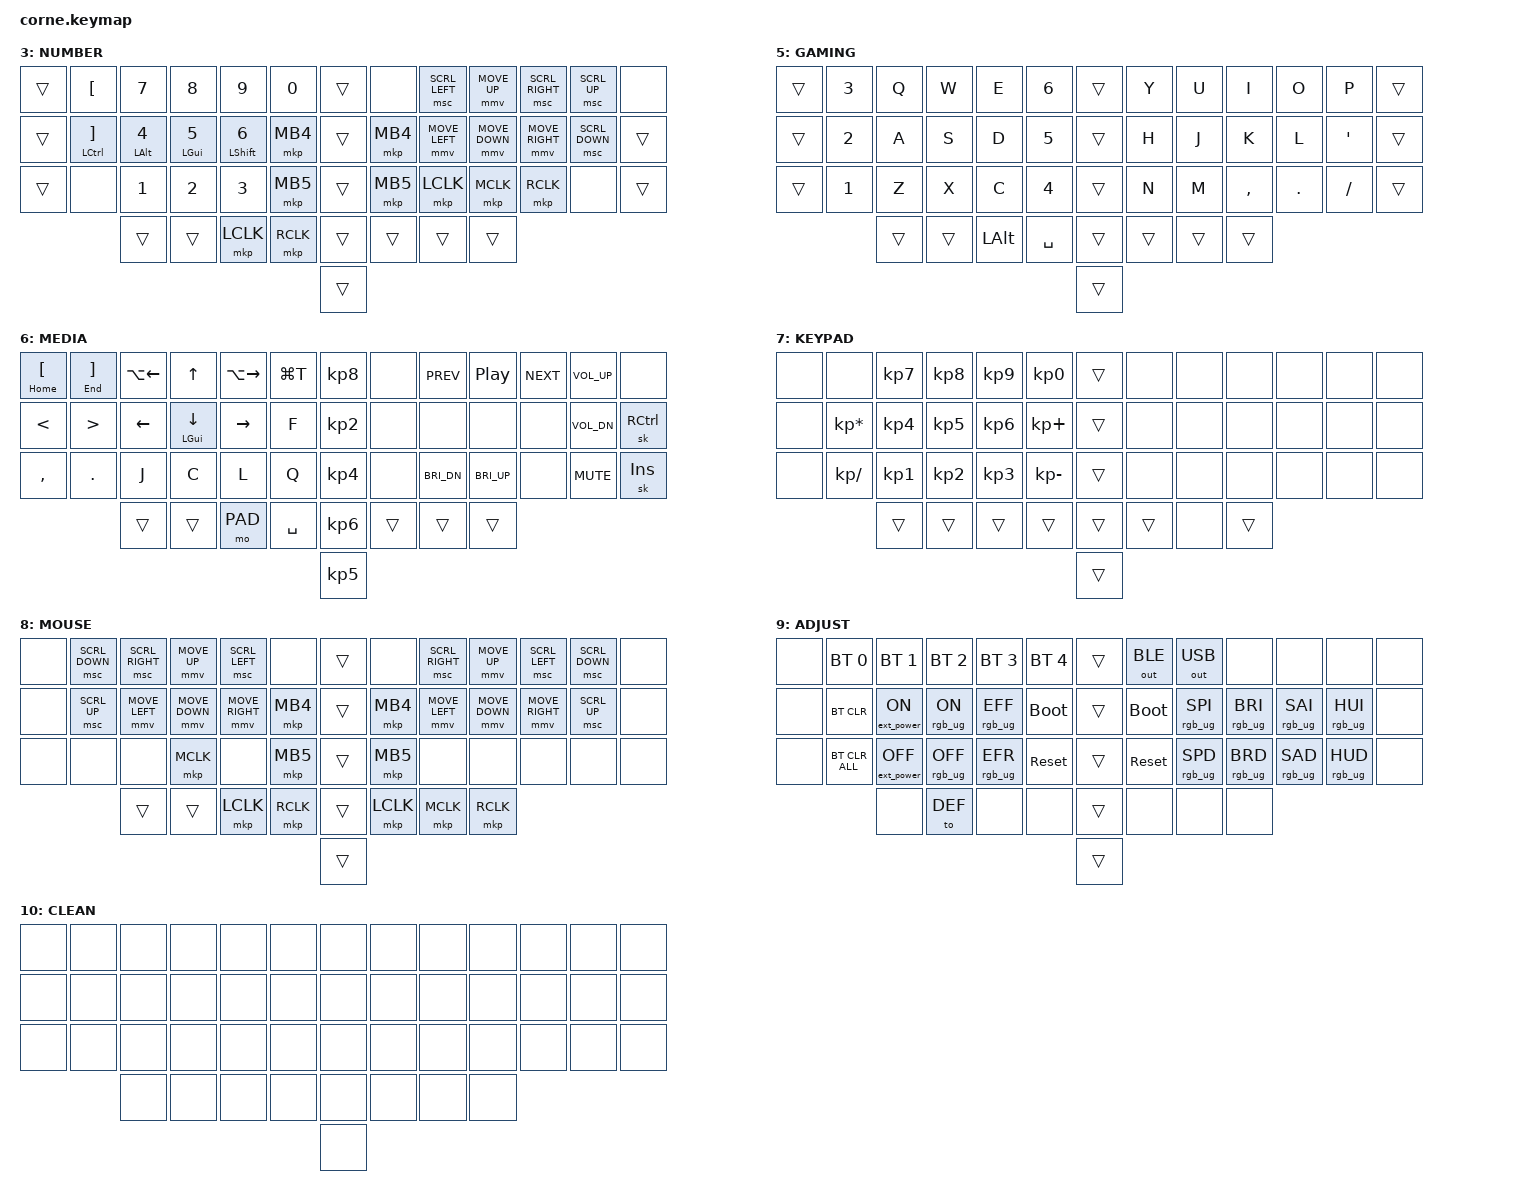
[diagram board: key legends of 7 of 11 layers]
#include <behaviors.dtsi>
#include <dt-bindings/zmk/bt.h>
#include <dt-bindings/zmk/ext_power.h>
#include <dt-bindings/zmk/keys.h>
#include <dt-bindings/zmk/mouse.h>
#include <dt-bindings/zmk/outputs.h>
#include <dt-bindings/zmk/rgb.h>
#include "zmk-helpers/helper.h"             // Urob's features
// #include "zmk-helpers/key-labels/42.h"      // Urob's features

// Define layer numbers
#define DEF 0
#define COL 1
#define NAV 2
#define NUM 3
#define FUN 4
#define GAM 5
#define MED 6
#define PAD 7
#define MOUSE 8
#define ADJ 9
#define CLE 10

// Define mouse action
#define ZMK_MOUSE_DEFAULT_MOVE_VAL 1500  // 600
#define ZMK_MOUSE_DEFAULT_SCRL_VAL 20    // 10

#define U_MS_U &mmv MOVE_UP
#define U_MS_D &mmv MOVE_DOWN
#define U_MS_L &mmv MOVE_LEFT
#define U_MS_R &mmv MOVE_RIGHT
#define U_WH_U &msc SCRL_UP
#define U_WH_D &msc SCRL_DOWN
#define U_WH_L &msc SCRL_LEFT
#define U_WH_R &msc SCRL_RIGHT

// ───────────────────────────────────────────────── Global settings ─────────────────────────────────────────────────
    #define QUICK_TAP_MS 175

    #define COMBO_TERM_FAST 18
    #define COMBO_TERM_SLOW 30

    #define COMBO_IDLE_FAST 150
    #define COMBO_IDLE_SLOW 50

    #define KEYS_L 0 1 2 3 4 5 13 14 15 16 17 18 26 27 28 29 30 31      // left hand
    #define KEYS_R 7 8 9 10 11 12 20 21 22 23 24 25 33 34 35 36 37 38   // right hand
    #define THUMBS 40 41 42 44 45 46                                    // thumbs
    #define STICK_R 6 19 32 43 47                                       // right joystick

    // #define HYP(HYPERKEY) &kp LC(LA(LS(LG(HYPERKEY))))
    // #define MEH(MEHKEY) &kp LC(LA(LS(MEHKEY)))

    // &sk {  // sticky-key config
    //     release-after-ms = <900>;    // release after 0.9s
    //     quick-release;               // no double capitalization when rolling keys
    // };

    &sl {  // sticky-layer config
        ignore-modifiers;               // allow chording sticky mods & layers
    };

    // &lt {  // layer-tap config
    //     flavor = "balanced";
    //     tapping-term-ms = <200>;
    //     quick-tap-ms = <QUICK_TAP_MS>;
    // };

    // &caps_word {  // mods deactivate caps-word, requires PR #1451
    //     /delete-property/ ignore-modifiers;
    // };

    &num_word {  // num-word, requires PR #1451
        layers = <NUM>;
        continue-list = <BSPC DEL DOT KP_DOT COMMA PLUS MINUS STAR FSLH EQUAL CARET PRCNT UP DOWN LEFT RIGHT TAB LBKT RBKT>;
        ignore-modifiers;
    };

    // Config from @caksoylar, defaults in comments
    &mmv {
        acceleration-exponent = <1>;        // 1
        time-to-max-speed-ms = <500>;       // 300
        delay-ms = <0>;                     // 0
    };

    &msc {
        acceleration-exponent = <1>;        // 0
        time-to-max-speed-ms = <40>;        // 300
        delay-ms = <0>;                     // 0
    };

// ───────────────────────────────────────────────── END Global settings ─────────────────────────────────────────────────

// ───────────────────────────────────────────────── Make new behavior ─────────────────────────────────────────────────
    // //example for define custom MOD_TAP
    // #define MAKE_HRM(NAME, HOLD, TAP, TRIGGER_POS) \
    //     ZMK_HOLD_TAP(NAME, \
    //         flavor = "balanced"; \
    //         tapping-term-ms = <280>; \
    //         quick-tap-ms = <QUICK_TAP_MS>; \
    //         require-prior-idle-ms = <150>; \
    //         bindings = <HOLD>, <TAP>; \
    //         hold-trigger-key-positions = <TRIGGER_POS>; \
    //         hold-trigger-on-release; \
    //     )
    // MAKE_HRM(hml, &kp, &kp, KEYS_R THUMBS)  // left-hand HRMs
    // MAKE_HRM(hml_repeat, &kp, &key_repeat, KEYS_R THUMBS)  // used for HRM-combo

    //     tri_MED: tri_MED {
    //         compatible = "zmk,behavior-tri-state";
    //         #binding-cells = <0>;
    //         bindings = <&tog MED>, <&none>, <&tog MED>;
    //         ignored-key-positions = <KEYS_L KEYS_R 40 41 42 44 46>;
    //         ignored-layers = <MED PAD>;
    //     };

    // #define MAKE_MO_TRI(NAME, HOLD, TAP) \
    // / { \
    //     behaviors { \
    //         NAME: NAME { \
    //             compatible = "zmk,behavior-hold-tap"; \
    //             #binding-cells = <2>; \
    //             bindings = <HOLD>, <TAP>; \
    //             flavor = "balanced"; \
    //             tapping-term-ms = <220>; \
    //         } \
    //     } \
    // }

    // MAKE_MO_TRI(mo_tMED, &mo, &tri_MED)
    //     mo_tMED: mo_tMED {
    //         compatible = "zmk,behavior-hold-tap";
    //         #binding-cells = <2>;
    //         bindings = <&mo>, <&tri_MED>;
    //         flavor = "balanced";
    //         tapping-term-ms = <220>;
    //     }

// ───────────────────────────────────────────────── END Make new behavior ─────────────────────────────────────────────────

/ {
    behaviors {
        // new sticky-layer config, delay duration, no quick-release, ignore-modifiers
        sls: sticky_layer_slow {
            compatible = "zmk,behavior-sticky-key";
            #binding-cells = <1>;
            bindings = <&mo>;
            release-after-ms = <2000>;                  // 1000
            ignore-modifiers;                           // allow chording sticky mods & layers
        };

        // new sticky-key config, delay duration, no quick-release, ignore-modifiers
        sks: sticky_key_slow {
            compatible = "zmk,behavior-sticky-key";
            #binding-cells = <1>;
            bindings = <&kp>;
            release-after-ms = <2000>;                  // 1000
            ignore-modifiers;                           // allow chording sticky mods & layers
        };

// ───────────────────────────────────────────────── Smart-shift, Caps-word, num-word; Tri-State, Swapper ─────────────────────────────────────────────────
        // tap: sticky-shift | shift + tap/ double-tap: caps-word | hold: shift
        smart_shft: smart_shift {
            compatible = "zmk,behavior-mod-morph";
            #binding-cells = <0>;
            bindings = <&sk LSHFT>, <&caps_word>;
            mods = <(MOD_LSFT)>;
        };

        nav_word: nav_word {
            #binding-cells = <0>;
            compatible = "zmk,behavior-caps-word";
            layers = <NAV>;
            continue-list = <SPACE BSPC DEL DOT KP_DOT COMMA PLUS MINUS STAR FSLH EQUAL CARET PRCNT UP DOWN LEFT RIGHT TAB>;
            ignore-numbers;
        };

        // mm_ret_sNum: enter_smartNumber {
        //    compatible = "zmk,behavior-mod-morph";
        //    #binding-cells = <0>;
        //    bindings = <&kp RET>, <&num_word>;
        //    mods = <(MOD_LSFT)>;
        // };

        tri_NUM: Tri-State_NUMBER {
            compatible = "zmk,behavior-tri-state";
            #binding-cells = <0>;
            bindings = <&tog NUM>, <&none>, <&tog NUM>;
            ignored-key-positions = <KEYS_L KEYS_R STICK_R 41 42 45 46 39>;
            ignored-layers = <NUM>;
        };

        tri_MED: Tri-State_MEDIA {
            compatible = "zmk,behavior-tri-state";
            #binding-cells = <0>;
            bindings = <&tog MED>, <&none>, <&tog MED>;
            ignored-key-positions = <KEYS_L KEYS_R STICK_R 41 42 45 46 39>;
            ignored-layers = <MED PAD>;
        };

        tri_PAD: Tri-State_KEYPAD {
            compatible = "zmk,behavior-tri-state";
            #binding-cells = <0>;
            bindings = <&tog PAD>, <&none>, <&tog PAD>;
            ignored-key-positions = <KEYS_L KEYS_R 41 42 44 45 46>;
            ignored-layers = <PAD>;
        };

        tri_MOUSE: Tri-State_MOUSE {
            compatible = "zmk,behavior-tri-state";
            #binding-cells = <0>;
            bindings = <&tog MOUSE>, <&none>, <&tog MOUSE>;
            ignored-key-positions = <KEYS_L KEYS_R STICK_R 41 42 44 45 46 39>;
            ignored-layers = <MOUSE>;
        };

        // cmd_tab swapper
        swapper_tab: swapper_tab {
            compatible = "zmk,behavior-tri-state";
            #binding-cells = <0>;
            bindings = <&kt LGUI>, <&kp TAB>, <&kt LGUI>;
            ignored-key-positions = <0 13>;
        };
// ───────────────────────────────────────────────── END Smart-shift, Caps-word, num-word; Tri-State, Swapper ─────────────────────────────────────────────────

// ───────────────────────────────────────────────── Tap Dance ─────────────────────────────────────────────────
    // arrows, arrows with modifier
        td_up: td_up {
            compatible = "zmk,behavior-tap-dance";
            #binding-cells = <0>;
            bindings = <&kp UP>, <&mt LG(UP) LA(UP)>;
            tapping-term-ms = <250>;
        };

        td_left: td_left {
            compatible = "zmk,behavior-tap-dance";
            #binding-cells = <0>;
            bindings = <&kp LEFT>, <&mt LG(LEFT) LA(LEFT)>;
            tapping-term-ms = <250>;
        };

        td_down: td_down {
            compatible = "zmk,behavior-tap-dance";
            #binding-cells = <0>;
            bindings = <&kp DOWN>, <&mt LG(DOWN) LA(DOWN)>;
            tapping-term-ms = <250>;
        };

        td_right: td_right {
            compatible = "zmk,behavior-tap-dance";
            #binding-cells = <0>;
            bindings = <&kp RIGHT>, <&mt LG(RIGHT) LA(RIGHT)>;
            tapping-term-ms = <250>;
        };

    // symbols
        td_DPAR: td_Doubel_PAR {
            compatible = "zmk,behavior-tap-dance";
            #binding-cells = <0>;
            bindings = <&mt RPAR LPAR>, <&m_DPAR>;
        };

        td_DBKT: td_Double_BKT {
            compatible = "zmk,behavior-tap-dance";
            #binding-cells = <0>;
            bindings = <&mt RBKT LBKT>, <&m_DBKT>;
        };

        td_DBRC: td_Double_BRC {
            compatible = "zmk,behavior-tap-dance";
            #binding-cells = <0>;
            bindings = <&mt RBRC LBRC>, <&m_DBRC>;
        };

        td_LTGT: td_LTGT {
            compatible = "zmk,behavior-tap-dance";
            #binding-cells = <0>;
            bindings = <&mt GT LT>, <&m_LTGT>;
        };
// ───────────────────────────────────────────────── END Tap Dance ─────────────────────────────────────────────────

// ───────────────────────────────────────────────── Hold-tap ─────────────────────────────────────────────────
    // define new behavior
        //  change flavor to balanced
        ltb: ltb {
            compatible = "zmk,behavior-hold-tap";
            #binding-cells = <2>;
            bindings = <&mo>, <&kp>;
            flavor = "balanced";
            tapping-term-ms = <200>;
        };

        //  hold to layer, quickly tap-tap holding to output key
        ltq: ltq {
            compatible = "zmk,behavior-hold-tap";
            #binding-cells = <2>;
            bindings = <&mo>, <&kp>;
            flavor = "balanced";
            tapping-term-ms = <220>;
            quick-tap-ms = <220>;
        };

        //  hold to momentary layer, tap to sticky layer
        mosls: mosls {
            compatible = "zmk,behavior-hold-tap";
            #binding-cells = <2>;
            bindings = <&mo>, <&sls>;
            flavor = "balanced";
            tapping-term-ms = <220>;
        };

        //  hold to momentary layer, tap to Tri-Stage_MEDIA
        mo_tMED: mo_tMED {
            compatible = "zmk,behavior-hold-tap";
            #binding-cells = <2>;
            bindings = <&mo>, <&tri_MED>;
            flavor = "balanced";
            tapping-term-ms = <220>;
            // quick-tap-ms = <200>;
        };

        //  hold to momentary layer, tap to Tri-Stage_KEYPAD
        mo_tPAD: mo_tPAD {
            compatible = "zmk,behavior-hold-tap";
            #binding-cells = <2>;
            bindings = <&mo>, <&tri_PAD>;
            flavor = "balanced";
            tapping-term-ms = <220>;
            // quick-tap-ms = <200>;
        };

        //  hold to momentary layer, tap to Tri-Stage_MOUSE
        mo_tMOUSE: mo_tMOUSE {
            compatible = "zmk,behavior-hold-tap";
            #binding-cells = <2>;
            bindings = <&mo>, <&tri_MOUSE>;
            flavor = "balanced";
            tapping-term-ms = <220>;
            // quick-tap-ms = <200>;
        };

    // infused-kim's Homerow-Mods
        hml: homerow_mod_left {
            compatible = "zmk,behavior-hold-tap";
            #binding-cells = <2>;
            bindings = <&kp>, <&kp>;

            flavor = "balanced";
            tapping-term-ms = <280>;
            quick-tap-ms = <QUICK_TAP_MS>;          // repeat on tap-into-hold
            require-prior-idle-ms = <150>;
            hold-trigger-key-positions = <KEYS_R THUMBS>;
            hold-trigger-on-release;                // delay positional check until key-release
        };

        hmr: homerow_mod_right {
            compatible = "zmk,behavior-hold-tap";
            #binding-cells = <2>;
            bindings = <&kp>, <&kp>;

            flavor = "balanced";
            tapping-term-ms = <280>;
            quick-tap-ms = <QUICK_TAP_MS>;
            require-prior-idle-ms = <150>;
            hold-trigger-key-positions = <KEYS_L THUMBS>;
            hold-trigger-on-release;
        };

        hmlq: hm_left_quick {
            compatible = "zmk,behavior-hold-tap";
            #binding-cells = <2>;
            bindings = <&kp>, <&kp>;

            flavor = "balanced";
            tapping-term-ms = <200>;
            quick-tap-ms = <QUICK_TAP_MS>;
            require-prior-idle-ms = <150>;
            hold-trigger-key-positions = <KEYS_R THUMBS>;
            // hold-trigger-on-release;
        };

        hmrq: hm_right_quick {
            compatible = "zmk,behavior-hold-tap";
            #binding-cells = <2>;
            bindings = <&kp>, <&kp>;

            flavor = "balanced";
            tapping-term-ms = <200>;
            quick-tap-ms = <QUICK_TAP_MS>;
            require-prior-idle-ms = <150>;
            hold-trigger-key-positions = <KEYS_L THUMBS>;
            // hold-trigger-on-release;
        };

    // Homerow-Mods for Combos
        hml_tMED: hml_Tri-State_MEDIA {
            compatible = "zmk,behavior-hold-tap";
            #binding-cells = <2>;
            bindings = <&kp>, <&tri_MED>;

            flavor = "balanced";
            tapping-term-ms = <280>;
            quick-tap-ms = <QUICK_TAP_MS>;
            require-prior-idle-ms = <150>;
            hold-trigger-key-positions = <KEYS_R THUMBS>;
            hold-trigger-on-release;
        };


// ───────────────────────────────────────────────── END Hold-tap ─────────────────────────────────────────────────
    };

    combos {
// ───────────────────────────────────────────────── Combos ─────────────────────────────────────────────────
        compatible = "zmk,combos";
    // left hand: horizontal
        // ZMK_COMBO(tab, &kp TAB, LT3 LT2, ALL, COMBO_TERM_FAST, COMBO_IDLE_FAST)
        cb_tab {
            bindings = <&kp TAB>;
            key-positions = <2 3>;
            timeout-ms = <COMBO_TERM_FAST>;
            require-prior-idle-ms = <COMBO_IDLE_FAST>;
        };

        // ZMK_COMBO(grave, &kp GRAVE, LM3 LM2, ALL, COMBO_TERM_FAST, COMBO_IDLE_FAST)
        cb_grave {
            bindings = <&hml LA(LGUI) GRAVE>;
            key-positions = <15 16>;
            timeout-ms = <COMBO_TERM_FAST>;
            require-prior-idle-ms = <COMBO_IDLE_FAST>;
        };

        // ZMK_COMBO(tilde, &kp TILDE, LM4 LM3, ALL, COMBO_TERM_FAST, COMBO_IDLE_FAST)
        cb_tilde {
            bindings = <&hml LC(LALT) TILDE>;
            key-positions = <14 15>;
            timeout-ms = <COMBO_TERM_FAST>;
            require-prior-idle-ms = <COMBO_IDLE_FAST>;
        };

        // ZMK_COMBO(repeat, &key_repeat, LT2 LT1, ALL, COMBO_TERM_FAST, COMBO_IDLE_FAST)
        cb_repeat {
            bindings = <&key_repeat>;
            key-positions = <3 4>;
            timeout-ms = <COMBO_TERM_FAST>;
            require-prior-idle-ms = <COMBO_IDLE_FAST>;
        };

        // ZMK_COMBO(L_enter, &kp RET, LM2 LM1, ALL, COMBO_TERM_FAST, COMBO_IDLE_FAST)
        cb_L_enter {
            bindings = <&hml LG(LSHFT) RET>;
            key-positions = <16 17>;
            timeout-ms = <COMBO_TERM_FAST>;
            require-prior-idle-ms = <COMBO_IDLE_FAST>;
        };

        // ZMK_COMBO(L_equal, &kp EQUAL, LB4 LB3, ALL, COMBO_TERM_FAST, COMBO_IDLE_FAST)
        cb_L_equal {
            bindings = <&kp EQUAL>;
            key-positions = <27 28>;
            timeout-ms = <COMBO_TERM_FAST>;
            require-prior-idle-ms = <COMBO_IDLE_FAST>;
        };

        // ZMK_COMBO(L_minus, &kp MINUS, LB3 LB2, ALL, COMBO_TERM_FAST, COMBO_IDLE_FAST)
        cb_L_minus {
            bindings = <&kp MINUS>;
            key-positions = <28 29>;
            timeout-ms = <COMBO_TERM_FAST>;
            require-prior-idle-ms = <COMBO_IDLE_FAST>;
        };

        // ZMK_COMBO(L_under, &kp UNDER, LB2 LB1, ALL, COMBO_TERM_FAST, COMBO_IDLE_FAST)
        cb_L_under {
            bindings = <&kp UNDER>;
            key-positions = <29 30>;
            timeout-ms = <COMBO_TERM_FAST>;
            require-prior-idle-ms = <COMBO_IDLE_FAST>;
        };

    // left hand: vertical
        //ZMK_COMBO(excl_qmark, &mt EXCL QMARK, LT4 LM4, ALL, COMBO_TERM_SLOW, COMBO_IDLE_SLOW)
        cb_excl_qmark {
            bindings = <&mt EXCL QMARK>;
            key-positions = <1 14>;
            timeout-ms = <COMBO_TERM_SLOW>;
            require-prior-idle-ms = <COMBO_IDLE_SLOW>;
        };

        //ZMK_COMBO(amps_at, &mt AMPS AT, LT3 LM3, ALL, COMBO_TERM_SLOW, COMBO_IDLE_SLOW)
        cb_amps_at {
            bindings = <&mt AMPS AT>;
            key-positions = <2 15>;
            timeout-ms = <COMBO_TERM_SLOW>;
            require-prior-idle-ms = <COMBO_IDLE_SLOW>;
        };

        //ZMK_COMBO(star_hash, &mt STAR HASH, LT2 LM2, ALL, COMBO_TERM_SLOW, COMBO_IDLE_SLOW)
        cb_star_hash {
            bindings = <&mt STAR HASH>;
            key-positions = <3 16>;
            timeout-ms = <COMBO_TERM_SLOW>;
            require-prior-idle-ms = <COMBO_IDLE_SLOW>;
        };

        //ZMK_COMBO(JPY_dllr, &mt LA(Y) DLLR, LT1 LM1, ALL, COMBO_TERM_SLOW, COMBO_IDLE_SLOW)
        cb_JPY_dollar {
            bindings = <&mt LA(Y) DLLR>;
            key-positions = <4 17>;
            timeout-ms = <COMBO_TERM_SLOW>;
            require-prior-idle-ms = <COMBO_IDLE_SLOW>;
        };

        //ZMK_COMBO(caret_prcnt, &mt CARET PRCNT, LT0 LM0, ALL, COMBO_TERM_SLOW, COMBO_IDLE_SLOW)
        cb_caret_prcnt {
            bindings = <&mt CARET PRCNT>;
            key-positions = <5 18>;
        };

        //ZMK_COMBO(semi_comma, &mt SEMICOLON COMMA, LM3 LB3, ALL, COMBO_TERM_SLOW, COMBO_IDLE_SLOW)
        cb_semi_comma {
            bindings = <&mt SEMICOLON COMMA>;
            key-positions = <15 28>;
            timeout-ms = <COMBO_TERM_SLOW>;
            require-prior-idle-ms = <COMBO_IDLE_SLOW>;
        };

        //ZMK_COMBO(colon_dot, &mt COLON DOT, LM2 LB2, ALL, COMBO_TERM_SLOW, COMBO_IDLE_SLOW)
        cb_colon_dot {
            bindings = <&mt COLON DOT>;
            key-positions = <16 29>;
        };

        //ZMK_COMBO(dqt_sqt, &mt DQT SQT, LM1 LB1, ALL, COMBO_TERM_SLOW, COMBO_IDLE_SLOW)
        cb_dqt_sqt {
            bindings = <&mt DQT SQT>;
            key-positions = <17 30>;
            timeout-ms = <COMBO_TERM_SLOW>;
            require-prior-idle-ms = <COMBO_IDLE_SLOW>;
        };

        //ZMK_COMBO(L_pipe, &kp PIPE, LM0 LB0, ALL, COMBO_TERM_SLOW, COMBO_IDLE_SLOW)
        cb_L_pipe {
            bindings = <&kp PIPE>;
            key-positions = <18 31>;
            timeout-ms = <COMBO_TERM_SLOW>;
            require-prior-idle-ms = <COMBO_IDLE_SLOW>;
        };

    // left hand: diagonal
        // ZMK_COMBO(prevTab, &kp LT, LM2 LB3, ALL, COMBO_TERM_SLOW, COMBO_IDLE_SLOW)
        cb_prevTab {
            bindings = <&kp LC(LS(TAB))>;
            key-positions = <3 15>;
            timeout-ms = <COMBO_TERM_SLOW>;
            require-prior-idle-ms = <COMBO_IDLE_SLOW>;
        };

        // ZMK_COMBO(nextTab, &kp GT, LM2 LB1, ALL, COMBO_TERM_SLOW, COMBO_IDLE_SLOW)
        cb_nextTab {
            bindings = <&kp LC(TAB)>;
            key-positions = <3 17>;
            timeout-ms = <COMBO_TERM_SLOW>;
            require-prior-idle-ms = <COMBO_IDLE_SLOW>;
        };

        // ZMK_COMBO(L_fslh, &kp FSLH, LT2 LM3, ALL, COMBO_TERM_SLOW, COMBO_IDLE_SLOW)
        cb_L_fslh {
            bindings = <&kp FSLH>;
            key-positions = <16 28>;
            timeout-ms = <COMBO_TERM_SLOW>;
            require-prior-idle-ms = <COMBO_IDLE_SLOW>;
        };

        // ZMK_COMBO(L_bslh, &kp BSLH, LT2 LM1, ALL, COMBO_TERM_SLOW, COMBO_IDLE_SLOW)
        cb_L_bslh {
            bindings = <&kp BSLH>;
            key-positions = <16 30>;
            timeout-ms = <COMBO_TERM_SLOW>;
            require-prior-idle-ms = <COMBO_IDLE_SLOW>;
        };

    // right hand: horizontal
        // ZMK_COMBO(R_enter, &kp RET, RM1 RM2, ALL, COMBO_TERM_FAST, COMBO_IDLE_FAST)
        cb_R_enter {
            bindings = <&hmr RS(RGUI) RET>;
            key-positions = <21 22>;
            timeout-ms = <COMBO_TERM_FAST>;
            require-prior-idle-ms = <COMBO_IDLE_FAST>;
        };

        // ZMK_COMBO(R_equal, &kp EQUAL, RM3 RM4, ALL, COMBO_TERM_FAST, COMBO_IDLE_FAST)
        cb_R_equal {
            bindings = <&hmr RA(RCTRL) EQUAL>;
            key-positions = <23 24>;
            timeout-ms = <COMBO_TERM_FAST>;
            require-prior-idle-ms = <COMBO_IDLE_FAST>;
        };

        // ZMK_COMBO(R_under, &kp UNDER, RB1 RB2, ALL, COMBO_TERM_FAST, COMBO_IDLE_FAST)
        cb_R_under {
            bindings = <&kp UNDER>;
            key-positions = <34 35>;
            timeout-ms = <COMBO_TERM_FAST>;
            require-prior-idle-ms = <COMBO_IDLE_FAST>;
        };

        // ZMK_COMBO(R_pipe, &kp PIPE, RB2 RB3, ALL, COMBO_TERM_FAST, COMBO_IDLE_FAST)
        cb_R_pipe {
            bindings = <&kp PIPE>;
            key-positions = <35 36>;
            timeout-ms = <COMBO_TERM_FAST>;
            require-prior-idle-ms = <COMBO_IDLE_FAST>;
        };

    // right hand: vertical
        // ZMK_COMBO(R_caret, &kp CARET, RT0 RM0, ALL, COMBO_TERM_SLOW, COMBO_IDLE_SLOW)
        cb_R_caret {
            bindings = <&kp CARET>;
            key-positions = <7 20>;
            timeout-ms = <COMBO_TERM_SLOW>;
            require-prior-idle-ms = <COMBO_IDLE_SLOW>;
        };

        // ZMK_COMBO(R_plus, &kp PLUS, RT1 RM1, ALL, COMBO_TERM_SLOW, COMBO_IDLE_SLOW)
        cb_R_plus {
            bindings = <&kp PLUS>;
            key-positions = <8 21>;
            timeout-ms = <COMBO_TERM_SLOW>;
            require-prior-idle-ms = <COMBO_IDLE_SLOW>;
        };

        // ZMK_COMBO(R_star, &kp STAR, RT2 RM2, ALL, COMBO_TERM_SLOW, COMBO_IDLE_SLOW)
        cb_R_star {
            bindings = <&kp STAR>;
            key-positions = <9 22>;
            timeout-ms = <COMBO_TERM_SLOW>;
            require-prior-idle-ms = <COMBO_IDLE_SLOW>;
        };

        // ZMK_COMBO(R_amps, &kp AMPS, RT3 RM3, ALL, COMBO_TERM_SLOW, COMBO_IDLE_SLOW)
        cb_R_amps {
            bindings = <&kp AMPS>;
            key-positions = <10 23>;
            timeout-ms = <COMBO_TERM_SLOW>;
            require-prior-idle-ms = <COMBO_IDLE_SLOW>;
        };

        // ZMK_COMBO(R_minus, &kp MINUS, RM1 RB1, ALL, COMBO_TERM_SLOW, COMBO_IDLE_SLOW)
        cb_R_minus {
            bindings = <&kp MINUS>;
            key-positions = <21 34>;
            timeout-ms = <COMBO_TERM_SLOW>;
            require-prior-idle-ms = <COMBO_IDLE_SLOW>;
        };

        // ZMK_COMBO(R_fslh, &kp FSLH, RM2 RB2, ALL, COMBO_TERM_SLOW, COMBO_IDLE_SLOW)
        cb_R_fslh {
            bindings = <&kp FSLH>;
            key-positions = <22 35>;
            timeout-ms = <COMBO_TERM_SLOW>;
            require-prior-idle-ms = <COMBO_IDLE_SLOW>;
        };

        // ZMK_COMBO(R_bslh, &kp BSLH, RM3 RB3, ALL, COMBO_TERM_SLOW, COMBO_IDLE_SLOW)
        cb_R_bslh {
            bindings = <&kp BSLH>;
            key-positions = <23 36>;
            timeout-ms = <COMBO_TERM_SLOW>;
            require-prior-idle-ms = <COMBO_IDLE_SLOW>;
        };

    // functional
        // ZMK_COMBO(bkfw, &mt LG(RBKT) LG(LBKT), LT5 LT4, ALL, COMBO_TERM_FAST, COMBO_IDLE_FAST)
        cb_BackForward {
            bindings = <&mt LG(RBKT) LG(LBKT)>;
            key-positions = <1 2>;
            timeout-ms = <COMBO_TERM_FAST>;
            require-prior-idle-ms = <COMBO_IDLE_FAST>;
        };

        // ZMK_COMBO(dbrc, &td_DBRC, LT1 LT0, ALL, COMBO_TERM_FAST, COMBO_IDLE_FAST)
        cb_dBRC {
            bindings = <&td_DBRC>;
            key-positions = <4 5>;
            timeout-ms = <COMBO_TERM_FAST>;
            require-prior-idle-ms = <COMBO_IDLE_FAST>;
        };

        // ZMK_COMBO(dpar, &td_DPAR, LM1 LM0, ALL, COMBO_TERM_FAST, COMBO_IDLE_FAST)
        cb_dPAR {
            bindings = <&td_DPAR>;
            key-positions = <17 18>;
            timeout-ms = <COMBO_TERM_FAST>;
            require-prior-idle-ms = <COMBO_IDLE_FAST>;
        };

        // ZMK_COMBO(LTGT, &LTGT, RM1 RB0, ALL, COMBO_TERM_SLOW, COMBO_IDLE_SLOW)
        cb_LTGT {
            bindings = <&td_LTGT>;
            key-positions = <17 31>;
            timeout-ms = <COMBO_TERM_SLOW>;
            require-prior-idle-ms = <COMBO_IDLE_SLOW>;
        };

        // ZMK_COMBO(dbkt, &td_DBKT, LB1 LB0, ALL, COMBO_TERM_FAST, COMBO_IDLE_FAST)
        cb_dBKT {
            bindings = <&td_DBKT>;
            key-positions = <30 31>;
            timeout-ms = <COMBO_TERM_FAST>;
            require-prior-idle-ms = <COMBO_IDLE_FAST>;
        };

    // Layer switch
        // ZMK_COMBO(tgCOL, &tog COL, LT3 LM4, ALL, COMBO_TERM_FAST, COMBO_IDLE_FAST)
        cb_tgCOL {
            bindings = <&tog COL>;
            key-positions = <2 14>;
        };

        // ZMK_COMBO(tgGAM, &tog GAM, LT1 LM0, ALL, COMBO_TERM_FAST, COMBO_IDLE_FAST)
        cb_tgGAM {
            bindings = <&tog GAM>;
            key-positions = <4 18>;
        };

        // ZMK_COMBO(tgADJ, &tog ADJ, RT3 RM4, ALL, COMBO_TERM_FAST, COMBO_IDLE_FAST)
        cb_tgADJ {
            bindings = <&tog ADJ>;
            key-positions = <10 24>;
        };

        // ZMK_COMBO(tgCLE, &tog CLE, RM3 RB4, ALL, COMBO_TERM_FAST, COMBO_IDLE_FAST)
        cb_tgCLE {
            bindings = <&tog CLE>;
            key-positions = <23 37>;
        };

        // ZMK_COMBO(cb_triMOUSE_L, &tri_MOUSE, LT3 LT1, ALL, COMBO_TERM_FAST, COMBO_IDLE_FAST)
        cb_triMOUSE_L {
            bindings = <&tri_MOUSE>;
            key-positions = <2 4>;
        };

        // ZMK_COMBO(cb_triMED, &tri_MED, LM3 LM1, ALL, COMBO_TERM_FAST, COMBO_IDLE_FAST)
        cb_triMED {
            bindings = <&hml_tMED LA(LSHFT) 0>;
            key-positions = <15 17>;
        };

        // ZMK_COMBO(numWord, &num_word, LB3 LB1, ALL, COMBO_TERM_FAST, COMBO_IDLE_FAST)
        cb_numWord {
            bindings = <&num_word>;
            key-positions = <28 30>;
        };

        // ZMK_COMBO(cb_triMOUSE_R, &tri_MOUSE, LT3 LT1, ALL, COMBO_TERM_FAST, COMBO_IDLE_FAST)
        cb_triMOUSE_R {
            bindings = <&tri_MOUSE>;
            key-positions = <8 10>;
        };

        // ZMK_COMBO(nvWord, &nav_word, RB1 RB3, ALL, COMBO_TERM_FAST, COMBO_IDLE_FAST)
        cb_nvWord {
            bindings = <&nav_word>;
            key-positions = <34 36>;
        };
// ───────────────────────────────────────────────── END Combos ─────────────────────────────────────────────────
    };

    macros {
// ───────────────────────────────────────────────── Macros ─────────────────────────────────────────────────
        m_DPAR: m_Double_PAR {
            compatible = "zmk,behavior-macro";
            #binding-cells = <0>;
            bindings = <&kp LPAR &kp RPAR &kp LEFT>;
        };

        m_DBKT: m_Doubel_BKT {
            compatible = "zmk,behavior-macro";
            #binding-cells = <0>;
            bindings = <&kp LBKT &kp RBKT &kp LEFT>;
        };

        m_DBRC: m_Double_BRC {
            compatible = "zmk,behavior-macro";
            #binding-cells = <0>;
            bindings = <&kp LBRC &kp RBRC &kp LEFT>;
        };

        m_LTGT: m_LT_GT {
            compatible = "zmk,behavior-macro";
            #binding-cells = <0>;
            bindings = <&kp LT &kp GT &kp LEFT>;
        };

        // holding layer and key
        m_MED_fn: m_MED_fn {
            compatible = "zmk,behavior-macro";
            wait-ms = <0>;
            tap-ms = <1>;
            #binding-cells = <0>;
            bindings = <&macro_press &mo MED &kp INS>
                     , <&macro_pause_for_release>
                     , <&macro_release &mo MED &kp INS>;
        };

        // holding FN key and tap
        fk: fk {
            compatible = "zmk,behavior-macro-one-param";
            wait-ms = <0>;
            #binding-cells = <1>;
            bindings = <&macro_press &kp INS>
                     , <&macro_wait_time 300>
                     , <&macro_param_1to1>
                     , <&kp MACRO_PLACEHOLDER>
                     , <&macro_release &kp INS>;
        };
// ───────────────────────────────────────────────── END Macros ─────────────────────────────────────────────────
    };


    keymap {
        compatible = "zmk,keymap";

        default_layer {
            display-name = "QWERTY";
            bindings = <
&mt INS TAB                 &kp Q         &kp W        &hml LC(LA(LS(LGUI))) E  &kp R          &kp T                &kp UP     &kp Y           &kp U          &hmr RC(RA(RS(RGUI))) I   &kp O        &kp P           &mt BSLH MINUS
&mt LC(LA(LS(LGUI))) GRAVE  &hml LCTRL A  &hml LALT S  &hml LGUI D              &hmlq LSHFT F  &kp G                &kp DOWN   &kp H           &hmrq RSHFT J  &hmr RGUI K               &hmr RALT L  &hmr RCTRL SQT  &mt LC(LA(LSHFT)) SEMI
&mt LSHFT CAPS              &kp Z         &kp X        &hml LC(LA(LSHFT)) C     &kp V          &kp B                &kp LEFT   &kp N           &kp M          &hmr LC(LA(LSHFT)) COMMA  &kp DOT      &kp FSLH        &kp INS
                                          &kp C_MUTE   &mt LGUI ESC             &ltb NAV BSPC  &ltq FUN SPACE       &kp RIGHT  &mosls FUN FUN  &ltb NUM RET   &smart_shft
                                                                                                                    &kp RET
            >;

            label = "QWERTY";
            sensor-bindings = <&inc_dec_kp LA(LS(C_VOL_UP)) LA(LS(C_VOL_DN))>;
        };

        colemak_layer {
            display-name = "ARSTGM";
            bindings = <
&trans  &trans  &trans       &hml LC(LA(LS(LGUI))) F  &kp P          &kp B          &trans  &kp J   &kp L          &hmr RC(RA(RS(RGUI))) U  &kp Y        &kp SQT       &trans
&trans  &trans  &hml LALT R  &hml LGUI S              &hmlq LSHFT T  &trans         &trans  &kp M   &hmrq RSHFT N  &hmr RGUI E              &hmr RALT I  &hmr RCTRL O  &trans
&trans  &trans  &trans       &trans                   &kp D          &kp V          &trans  &kp K   &kp H          &trans                   &trans       &trans        &trans
                &trans       &trans                   &trans         &trans         &trans  &trans  &trans         &trans
                                                                                    &trans
            >;
        };

        navigation_layer {
            display-name = "NAVI";
            bindings = <
&trans  &kp PG_UP  &kp HOME  &td_up    &kp END    &kp PRCNT     &mmv MOVE_UP     &kp CARET  &kp N7          &hmr RC(RA(RS(RGUI))) N8  &kp N9        &kp N0           &kp BSLH
&trans  &kp PG_DN  &td_left  &td_down  &td_right  &kp RET       &mmv MOVE_DOWN   &kp PLUS   &hmrq RSHFT N4  &hmr RGUI N5              &hmr RALT N6  &hmr RCTRL STAR  &mt LC(LA(LSHFT)) EQUAL
&trans  &sk LCTRL  &sk LALT  &sk LGUI  &sk LSHFT  &kp DEL       &mmv MOVE_LEFT   &kp MINUS  &kp N1          &hmr LC(LA(LSHFT)) N2     &kp N3        &kp FSLH         &trans
                   &trans    &trans    &trans     &trans        &mmv MOVE_RIGHT  &trans     &kp KP_DOT      &trans
                                                                &mkp MCLK
            >;
        };

        number_layer {
            display-name = "NUMBER";
            bindings = <
&trans  &kp LBKT         &kp N7        &kp N8        &kp N9          &kp N0         &trans  &none     &msc SCRL_LEFT  &mmv MOVE_UP     &msc SCRL_RIGHT  &msc SCRL_UP    &none
&trans  &hml LCTRL RBKT  &hml LALT N4  &hml LGUI N5  &hmlq LSHFT N6  &mkp MB4       &trans  &mkp MB4  &mmv MOVE_LEFT  &mmv MOVE_DOWN   &mmv MOVE_RIGHT  &msc SCRL_DOWN  &trans
&trans  &none            &kp N1        &kp N2        &kp N3          &mkp MB5       &trans  &mkp MB5  &mkp LCLK       &mkp MCLK        &mkp RCLK        &none           &trans
                         &trans        &trans        &mkp LCLK       &mkp RCLK      &trans  &trans    &trans          &trans
                                                                                    &trans
            >;
        };

        function_layer {
            display-name = "FUNC";
            bindings = <
&trans  &none              &none              &none          &none          &kp LS(LG(T))       &trans  &kp LC(F2)    &kp F7  &kp F8  &kp F9  &kp F12  &none
&trans  &kp LC(LA(LSHFT))  &mkp LCLK          &mkp MCLK      &mkp RCLK      &kp LG(H)           &trans  &kp LC(F3)    &kp F4  &kp F5  &kp F6  &kp F11  &sk RCTRL
&trans  &kp LG(K)          &kp LA(LS(LG(V)))  &kp LA(LG(C))  &kp LA(LG(V))  &kp LA(LG(H))       &trans  &none         &kp F1  &kp F2  &kp F3  &kp F10  &sk INS
                           &kp C_PP           &trans         &trans         &trans              &trans  &mo_tMED MED  &trans  &trans
                                                                                                &trans
            >;

            label = "FUNC";
            sensor-bindings = <&inc_dec_kp C_NEXT C_PREV>;
        };

        gaming_layer {
            display-name = "GAMING";
            bindings = <
&trans  &kp N3  &kp Q   &kp W   &kp E     &kp N6            &trans  &kp Y   &kp U   &kp I      &kp O    &kp P     &trans
&trans  &kp N2  &kp A   &kp S   &kp D     &kp N5            &trans  &kp H   &kp J   &kp K      &kp L    &kp SQT   &trans
&trans  &kp N1  &kp Z   &kp X   &kp C     &kp N4            &trans  &kp N   &kp M   &kp COMMA  &kp DOT  &kp FSLH  &trans
                &trans  &trans  &kp LALT  &kp SPACE         &trans  &trans  &trans  &trans
                                                            &trans
            >;
        };

        media_layer {
            display-name = "MEDIA";
            bindings = <
&mt HOME LBKT  &mt END RBKT  &kp LA(LEFT)  &kp UP          &kp LA(RIGHT)  &kp LG(T)     &kp KP_N8  &none   &kp C_PREV     &kp C_PP      &kp C_NEXT  &kp C_VOL_UP  &none
&kp LT         &kp GT        &kp LEFT      &hml LGUI DOWN  &kp RIGHT      &kp F         &kp KP_N2  &none   &none          &none         &none       &kp C_VOL_DN  &sk RCTRL
&kp COMMA      &kp DOT       &kp J         &kp C           &kp L          &kp Q         &kp KP_N4  &none   &kp C_BRI_DN   &kp C_BRI_UP  &none       &kp C_MUTE    &sk INS
                             &trans        &trans          &mo PAD        &kp SPACE     &kp KP_N6  &trans  &trans         &trans
                                                                                        &kp KP_N5
            >;
        };

        keypad_layer {
            display-name = "KEYPAD";
            bindings = <
&none  &none            &kp KP_N7  &kp KP_N8  &kp KP_N9  &kp KP_N0          &trans  &none   &none  &none   &none  &none  &none
&none  &kp KP_MULTIPLY  &kp KP_N4  &kp KP_N5  &kp KP_N6  &kp KP_PLUS        &trans  &none   &none  &none   &none  &none  &none
&none  &kp KP_SLASH     &kp KP_N1  &kp KP_N2  &kp KP_N3  &kp KP_MINUS       &trans  &none   &none  &none   &none  &none  &none
                        &trans     &trans     &trans     &trans             &trans  &trans  &none  &trans
                                                                            &trans
            >;
        };

        mouse_layer {
            display-name = "MOUSE";
            bindings = <
&none  &msc SCRL_DOWN  &msc SCRL_RIGHT  &mmv MOVE_UP    &msc SCRL_LEFT   &none          &trans  &none      &msc SCRL_RIGHT  &mmv MOVE_UP    &msc SCRL_LEFT   &msc SCRL_DOWN  &none
&none  &msc SCRL_UP    &mmv MOVE_LEFT   &mmv MOVE_DOWN  &mmv MOVE_RIGHT  &mkp MB4       &trans  &mkp MB4   &mmv MOVE_LEFT   &mmv MOVE_DOWN  &mmv MOVE_RIGHT  &msc SCRL_UP    &none
&none  &none           &none            &mkp MCLK       &none            &mkp MB5       &trans  &mkp MB5   &none            &none           &none            &none           &none
                       &trans           &trans          &mkp LCLK        &mkp RCLK      &trans  &mkp LCLK  &mkp MCLK        &mkp RCLK
                                                                                        &trans
            >;
        };

        adjust_layer {
            display-name = "ADJUST";
            bindings = <
&none  &bt BT_SEL 0    &bt BT_SEL 1       &bt BT_SEL 2     &bt BT_SEL 3     &bt BT_SEL 4    &trans  &out OUT_BLE  &out OUT_USB     &none            &none            &none            &none
&none  &bt BT_CLR      &ext_power EP_ON   &rgb_ug RGB_ON   &rgb_ug RGB_EFF  &bootloader     &trans  &bootloader   &rgb_ug RGB_SPI  &rgb_ug RGB_BRI  &rgb_ug RGB_SAI  &rgb_ug RGB_HUI  &none
&none  &bt BT_CLR_ALL  &ext_power EP_OFF  &rgb_ug RGB_OFF  &rgb_ug RGB_EFR  &sys_reset      &trans  &sys_reset    &rgb_ug RGB_SPD  &rgb_ug RGB_BRD  &rgb_ug RGB_SAD  &rgb_ug RGB_HUD  &none
                       &none              &to DEF          &none            &none           &trans  &none         &none            &none
                                                                                            &trans
            >;
        };

        clean_layer {
            display-name = "CLEAN";
            bindings = <
&none  &none  &none  &none    &none  &none      &none  &none  &none  &none  &none  &none  &none
&none  &none  &none  &none    &none  &none      &none  &none  &none  &none  &none  &none  &none
&none  &none  &none  &none    &none  &none      &none  &none  &none  &none  &none  &none  &none
              &none  &none    &none  &none      &none  &none  &none  &none
                                                &none
            >;
        };
    };
};
